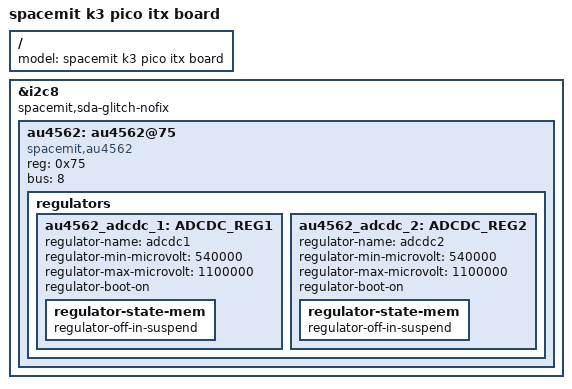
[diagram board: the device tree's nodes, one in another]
// SPDX-License-Identifier: GPL-2.0
/*
 * k3 pico itx board device tree (U-Boot).
 *
 * Copyright (C) 2025 SPACEMIT Micro Limited
 */

#include "k3-pico.dtsi"

/ {
	model = "spacemit k3 pico itx board";
};

&i2c8 {
	spacemit,sda-glitch-nofix;

	au4562: au4562@75 {
		compatible = "spacemit,au4562";
		reg = <0x75>;
		bus = <8>;
		u-boot,dm-spl;

		regulators {
			u-boot,dm-spl;

			au4562_adcdc_1: ADCDC_REG1 {
				regulator-name = "adcdc1";
				regulator-min-microvolt = <540000>;
				regulator-max-microvolt = <1100000>;
				regulator-boot-on;
				u-boot,dm-spl;
				regulator-state-mem {
					regulator-off-in-suspend;
				};
			};

			au4562_adcdc_2: ADCDC_REG2 {
				regulator-name = "adcdc2";
				regulator-min-microvolt = <540000>;
				regulator-max-microvolt = <1100000>;
				regulator-boot-on;
				u-boot,dm-spl;
				regulator-state-mem {
					regulator-off-in-suspend;
				};
			};
		};
	};
};
